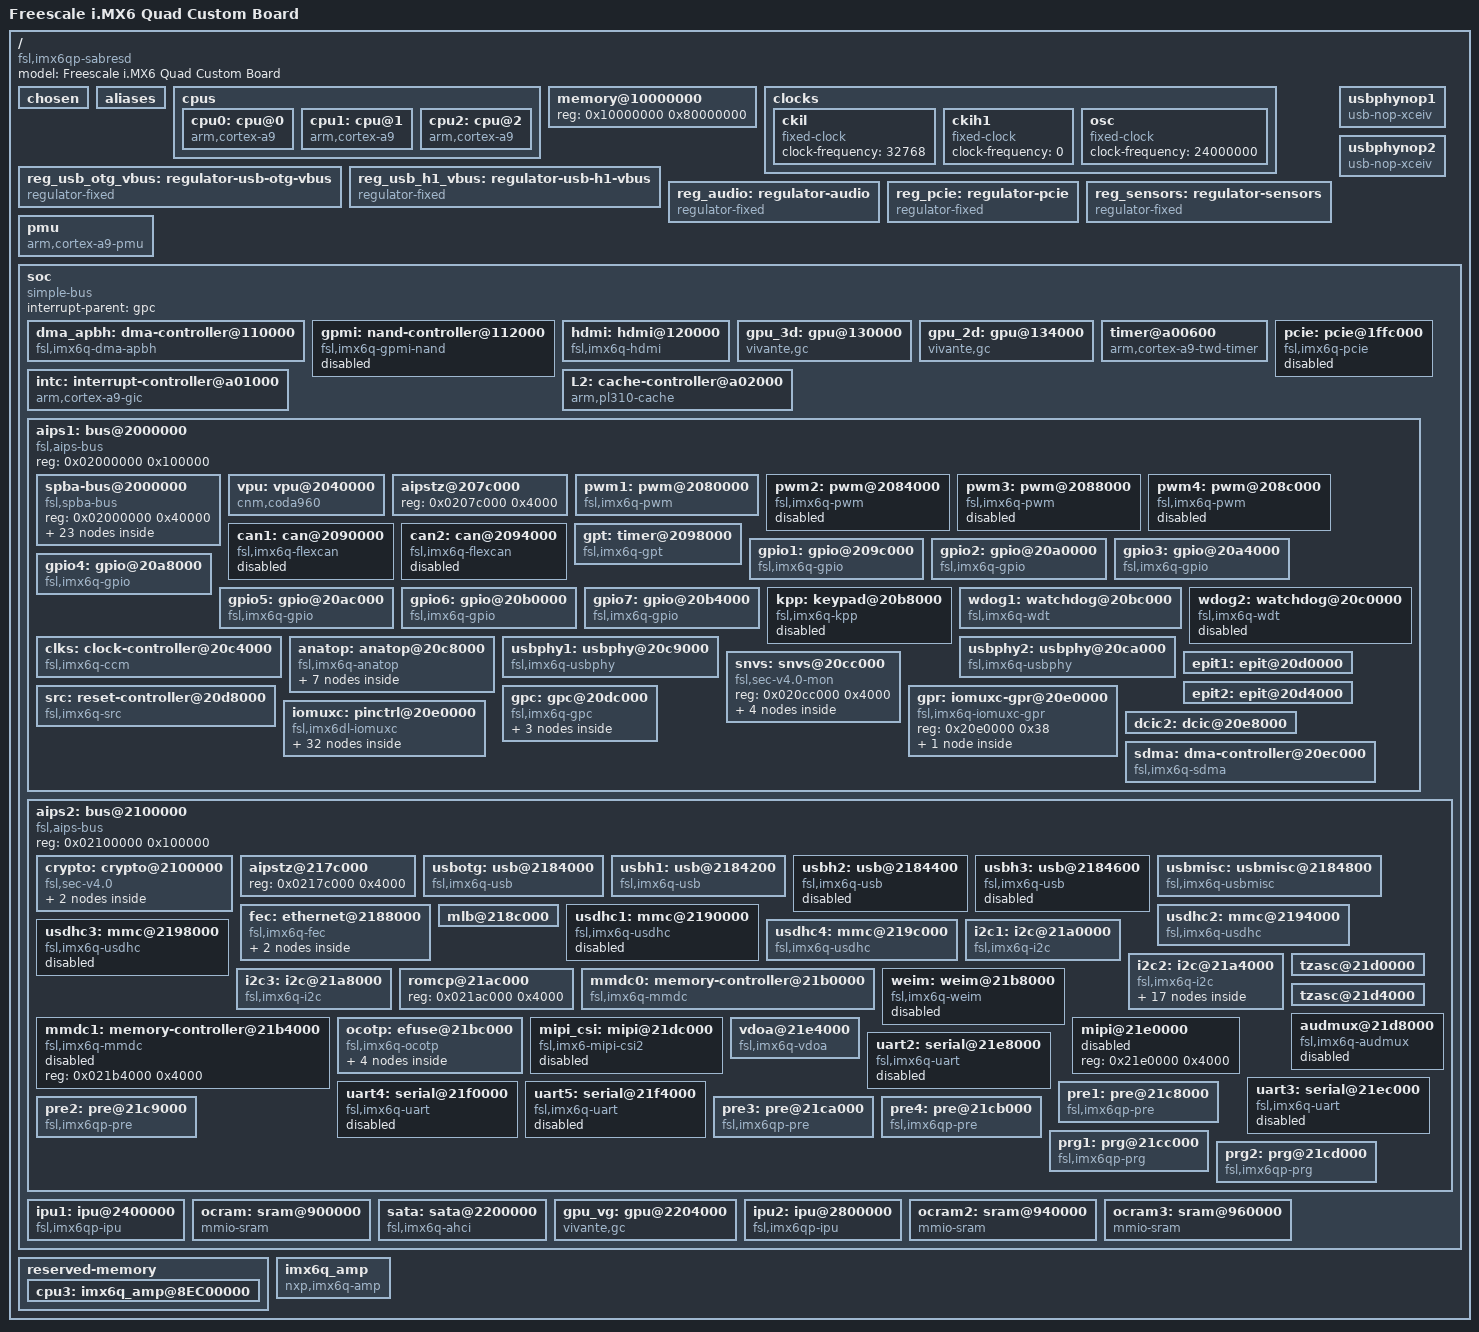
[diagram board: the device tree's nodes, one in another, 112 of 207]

/dts-v1/;
#include <dt-bindings/clock/imx6qdl-clock.h>
#include <dt-bindings/gpio/gpio.h>
#include <dt-bindings/input/input.h>
#include <dt-bindings/interrupt-controller/arm-gic.h>
#include <dt-bindings/interrupt-controller/irq.h>
#include "imx6q-pinfunc.h"
/ {
    #address-cells = <0x1>;
    #size-cells = <0x1>;
    model = "Freescale i.MX6 Quad Custom Board";
    compatible = "fsl,imx6qp-sabresd","fsl,imx6qp";

    chosen {
        stdout-path = "/soc/bus@2000000/spba-bus@2000000/serial@2020000";
    };

    aliases {
        ethernet0 = "/soc/bus@2100000/ethernet@2188000";
        can0 = "/soc/bus@2000000/can@2090000";
        can1 = "/soc/bus@2000000/can@2094000";
        gpio0 = "/soc/bus@2000000/gpio@209c000";
        gpio1 = "/soc/bus@2000000/gpio@20a0000";
        gpio2 = "/soc/bus@2000000/gpio@20a4000";
        gpio3 = "/soc/bus@2000000/gpio@20a8000";
        gpio4 = "/soc/bus@2000000/gpio@20ac000";
        gpio5 = "/soc/bus@2000000/gpio@20b0000";
        gpio6 = "/soc/bus@2000000/gpio@20b4000";
        i2c0 = "/soc/bus@2100000/i2c@21a0000";
        i2c1 = "/soc/bus@2100000/i2c@21a4000";
        i2c2 = "/soc/bus@2100000/i2c@21a8000";
        ipu0 = "/soc/ipu@2400000";
        mmc0 = "/soc/bus@2100000/mmc@2190000";
        mmc1 = "/soc/bus@2100000/mmc@2194000";
        mmc2 = "/soc/bus@2100000/mmc@2198000";
        mmc3 = "/soc/bus@2100000/mmc@219c000";
        serial0 = "/soc/bus@2000000/spba-bus@2000000/serial@2020000";
        serial1 = "/soc/bus@2100000/serial@21e8000";
        serial2 = "/soc/bus@2100000/serial@21ec000";
        serial3 = "/soc/bus@2100000/serial@21f0000";
        serial4 = "/soc/bus@2100000/serial@21f4000";
        spi0 = "/soc/bus@2000000/spba-bus@2000000/spi@2008000";
        spi1 = "/soc/bus@2000000/spba-bus@2000000/spi@200c000";
        spi2 = "/soc/bus@2000000/spba-bus@2000000/spi@2010000";
        spi3 = "/soc/bus@2000000/spba-bus@2000000/spi@2014000";
        usb0 = "/soc/bus@2100000/usb@2184000";
        usb1 = "/soc/bus@2100000/usb@2184200";
        usb2 = "/soc/bus@2100000/usb@2184400";
        usb3 = "/soc/bus@2100000/usb@2184600";
        usbphy0 = "/soc/bus@2000000/usbphy@20c9000";
        usbphy1 = "/soc/bus@2000000/usbphy@20ca000";
        ipu1 = "/soc/ipu@2800000";
        spi4 = "/soc/bus@2000000/spba-bus@2000000/spi@2018000";
    };
    cpus {
        #address-cells = <1>;
        #size-cells = <0>;

        cpu0: cpu@0 {
            compatible = "arm,cortex-a9";
            device_type = "cpu";
            reg = <0>;
            next-level-cache = <&L2>;
            operating-points = <
                /* kHz    uV */
                1200000 1275000
                996000  1250000
                852000  1250000
                792000  1175000
                396000  975000
            >;
            fsl,soc-operating-points = <
                /* ARM kHz  SOC-PU uV */
                1200000 1275000
                996000  1250000
                852000  1250000
                792000  1175000
                396000  1175000
            >;
            clock-latency = <61036>; /* two CLK32 periods */
            #cooling-cells = <2>;
            clocks = <&clks IMX6QDL_CLK_ARM>,
                 <&clks IMX6QDL_CLK_PLL2_PFD2_396M>,
                 <&clks IMX6QDL_CLK_STEP>,
                 <&clks IMX6QDL_CLK_PLL1_SW>,
                 <&clks IMX6QDL_CLK_PLL1_SYS>,
				 <&clks IMX6QDL_CLK_PLL1>,
				 <&clks IMX6QDL_PLL1_BYPASS>,
				 <&clks IMX6QDL_PLL1_BYPASS_SRC>;
            clock-names = "arm", "pll2_pfd2_396m", "step",
                      "pll1_sw", "pll1_sys","pll1","pll1_bypass", "pll1_bypass_src";
            arm-supply = <&reg_arm>;
            pu-supply = <&reg_pu>;
            soc-supply = <&reg_soc>;
            nvmem-cells = <&cpu_speed_grade>;
            nvmem-cell-names = "speed_grade";
        };

        cpu1: cpu@1 {
            compatible = "arm,cortex-a9";
            device_type = "cpu";
            reg = <1>;
            next-level-cache = <&L2>;
            operating-points = <
                /* kHz    uV */
                1200000 1275000
                996000  1250000
                852000  1250000
                792000  1175000
                396000  975000
            >;
            fsl,soc-operating-points = <
                /* ARM kHz  SOC-PU uV */
                1200000 1275000
                996000  1250000
                852000  1250000
                792000  1175000
                396000  1175000
            >;
            clock-latency = <61036>; /* two CLK32 periods */
            #cooling-cells = <2>;
            clocks = <&clks IMX6QDL_CLK_ARM>,
                 <&clks IMX6QDL_CLK_PLL2_PFD2_396M>,
                 <&clks IMX6QDL_CLK_STEP>,
                 <&clks IMX6QDL_CLK_PLL1_SW>,
                 <&clks IMX6QDL_CLK_PLL1_SYS>,
				 <&clks IMX6QDL_CLK_PLL1>,
				 <&clks IMX6QDL_PLL1_BYPASS>,
				 <&clks IMX6QDL_PLL1_BYPASS_SRC>;
            clock-names = "arm", "pll2_pfd2_396m", "step",
                      "pll1_sw", "pll1_sys","pll1","pll1_bypass", "pll1_bypass_src";
            
		    arm-supply = <&reg_arm>;
            pu-supply = <&reg_pu>;
            soc-supply = <&reg_soc>;
        };

        cpu2: cpu@2 {
            compatible = "arm,cortex-a9";
            device_type = "cpu";
            reg = <2>;
            next-level-cache = <&L2>;
            operating-points = <
                /* kHz    uV */
                1200000 1275000
                996000  1250000
                852000  1250000
                792000  1175000
                396000  975000
            >;
            fsl,soc-operating-points = <
                /* ARM kHz  SOC-PU uV */
                1200000 1275000
                996000  1250000
                852000  1250000
                792000  1175000
                396000  1175000
            >;
            clock-latency = <61036>; /* two CLK32 periods */
            #cooling-cells = <2>;
            clocks = <&clks IMX6QDL_CLK_ARM>,
                 <&clks IMX6QDL_CLK_PLL2_PFD2_396M>,
                 <&clks IMX6QDL_CLK_STEP>,
                 <&clks IMX6QDL_CLK_PLL1_SW>,
                 <&clks IMX6QDL_CLK_PLL1_SYS>,
    			 <&clks IMX6QDL_CLK_PLL1>,
				 <&clks IMX6QDL_PLL1_BYPASS>,
				 <&clks IMX6QDL_PLL1_BYPASS_SRC>;
            clock-names = "arm", "pll2_pfd2_396m", "step",
                      "pll1_sw", "pll1_sys","pll1","pll1_bypass", "pll1_bypass_src";
			arm-supply = <&reg_arm>;
            pu-supply = <&reg_pu>;
            soc-supply = <&reg_soc>;
        };

//         cpu3: cpu@3 {
//             compatible = "arm,cortex-a9";
//             device_type = "cpu";
//             reg = <3>;
//             next-level-cache = <&L2>;
//             operating-points = <
//                 /* kHz    uV */
//                 1200000 1275000
//                 996000  1250000
//                 852000  1250000
//                 792000  1175000
//                 396000  975000
//             >;
//             fsl,soc-operating-points = <
//                 /* ARM kHz  SOC-PU uV */
//                 1200000 1275000
//                 996000  1250000
//                 852000  1250000
//                 792000  1175000
//                 396000  1175000
//             >;
//             clock-latency = <61036>; /* two CLK32 periods */
//             #cooling-cells = <2>;
//             clocks = <&clks IMX6QDL_CLK_ARM>,
//                  <&clks IMX6QDL_CLK_PLL2_PFD2_396M>,
//                  <&clks IMX6QDL_CLK_STEP>,
//                  <&clks IMX6QDL_CLK_PLL1_SW>,
//                  <&clks IMX6QDL_CLK_PLL1_SYS>,
//         		 <&clks IMX6QDL_CLK_PLL1>,
// 				 <&clks IMX6QDL_PLL1_BYPASS>,
// 				 <&clks IMX6QDL_PLL1_BYPASS_SRC>;
//             clock-names = "arm", "pll2_pfd2_396m", "step",
//                       "pll1_sw", "pll1_sys","pll1","pll1_bypass", "pll1_bypass_src";
// 			arm-supply = <&reg_arm>;
//             pu-supply = <&reg_pu>;
//             soc-supply = <&reg_soc>;
//         };

    };
    memory@10000000 {
        device_type = "memory";
        reg = <0x10000000 0x80000000>;
    };
    
    clocks {

        ckil {
            compatible = "fixed-clock";
            #clock-cells = <0>;
            clock-frequency = <32768>;
        };

        ckih1 {
            compatible = "fixed-clock";
            #clock-cells = <0>;
            clock-frequency = <0>;
        };

        osc {
            compatible = "fixed-clock";
            #clock-cells = <0>;
            clock-frequency = <24000000>;
        };
    };
    
    reg_usb_otg_vbus: regulator-usb-otg-vbus {
        compatible = "regulator-fixed";
        regulator-name = "usb_otg_vbus";
        regulator-min-microvolt = <5000000>;
        regulator-max-microvolt = <5000000>;
        gpio = <&gpio3 22 GPIO_ACTIVE_HIGH>;
        enable-active-high;
        vin-supply = <&swbst_reg>;
    };

    reg_usb_h1_vbus: regulator-usb-h1-vbus {
        compatible = "regulator-fixed";
        regulator-name = "usb_h1_vbus";
        regulator-min-microvolt = <5000000>;
        regulator-max-microvolt = <5000000>;
        gpio = <&gpio1 29 GPIO_ACTIVE_HIGH>;
        enable-active-high;
        vin-supply = <&swbst_reg>;
    };

    reg_audio: regulator-audio {
        compatible = "regulator-fixed";
        regulator-name = "wm8962-supply";
        gpio = <&gpio4 10 GPIO_ACTIVE_HIGH>;
        enable-active-high;
    };

    reg_pcie: regulator-pcie {
        compatible = "regulator-fixed";
        pinctrl-names = "default";
        //pinctrl-0 = <&pinctrl_pcie_reg>;
        regulator-name = "MPCIE_3V3";
        regulator-min-microvolt = <3300000>;
        regulator-max-microvolt = <3300000>;
        //gpio = <&gpio3 19 GPIO_ACTIVE_HIGH>;
        enable-active-high;
    };

    reg_sensors: regulator-sensors {
        compatible = "regulator-fixed";
        pinctrl-names = "default";
        pinctrl-0 = <&pinctrl_sensors_reg>;
        regulator-name = "sensors-supply";
        regulator-min-microvolt = <3300000>;
        regulator-max-microvolt = <3300000>;
        gpio = <&gpio2 31 GPIO_ACTIVE_HIGH>;
        enable-active-high;
    };

    pmu: pmu {
        compatible = "arm,cortex-a9-pmu";
        interrupt-parent = <&gpc>;
        interrupts = <0 94 IRQ_TYPE_LEVEL_HIGH>;
    };

    usbphynop1: usbphynop1 {
                compatible = "usb-nop-xceiv";
                #phy-cells = <0>;
            };

    usbphynop2: usbphynop2 {
                compatible = "usb-nop-xceiv";
                #phy-cells = <0>;
            };
             
    soc: soc {
        #address-cells = <1>;
        #size-cells = <1>;
        compatible = "simple-bus";
        interrupt-parent = <&gpc>;
        ranges;

        dma_apbh: dma-controller@110000 {
            compatible = "fsl,imx6q-dma-apbh", "fsl,imx28-dma-apbh";
            reg = <0x00110000 0x2000>;
            interrupts = <0 13 IRQ_TYPE_LEVEL_HIGH>,
                     <0 13 IRQ_TYPE_LEVEL_HIGH>,
                     <0 13 IRQ_TYPE_LEVEL_HIGH>,
                     <0 13 IRQ_TYPE_LEVEL_HIGH>;
			interrupt-names = "gpmi0", "gpmi1", "gpmi2", "gpmi3";
            #dma-cells = <1>;
            dma-channels = <4>;
            clocks = <&clks IMX6QDL_CLK_APBH_DMA>;
        };

        gpmi: nand-controller@112000 {
            compatible = "fsl,imx6q-gpmi-nand";
            reg = <0x00112000 0x2000>, <0x00114000 0x2000>;
            reg-names = "gpmi-nand", "bch";
            interrupts = <0 15 IRQ_TYPE_LEVEL_HIGH>;
            interrupt-names = "bch";
            clocks = <&clks IMX6QDL_CLK_GPMI_IO>,
                 <&clks IMX6QDL_CLK_GPMI_APB>,
                 <&clks IMX6QDL_CLK_GPMI_BCH>,
                 <&clks IMX6QDL_CLK_GPMI_BCH_APB>,
                 <&clks IMX6QDL_CLK_PER1_BCH>;
            clock-names = "gpmi_io", "gpmi_apb", "gpmi_bch",
                      "gpmi_bch_apb", "per1_bch";
            dmas = <&dma_apbh 0>;
            dma-names = "rx-tx";
            status = "disabled";
        };

        hdmi: hdmi@120000 {
            reg = <0x00120000 0x9000>;
            interrupts = <0 115 0x04>;
            gpr = <&gpr>;
            clocks = <&clks IMX6QDL_CLK_HDMI_IAHB>,
                 <&clks IMX6QDL_CLK_HDMI_ISFR>;
            clock-names = "iahb", "isfr";
            status = "okay";
            compatible = "fsl,imx6q-hdmi";
            pinctrl-names = "default";
            pinctrl-0 = <&pinctrl_hdmi_cec>;
            ddc-i2c-bus = <&i2c2>;
        };

        gpu_3d: gpu@130000 {
            compatible = "vivante,gc";
            reg = <0x00130000 0x4000>;
            interrupts = <0 9 IRQ_TYPE_LEVEL_HIGH>;
            clocks = <&clks IMX6QDL_CLK_GPU3D_AXI>,
                 <&clks IMX6QDL_CLK_GPU3D_CORE>,
                 <&clks IMX6QDL_CLK_GPU3D_SHADER>;
            clock-names = "bus", "core", "shader";
            power-domains = <&pd_pu>;
            #cooling-cells = <2>;
        };

        gpu_2d: gpu@134000 {
            compatible = "vivante,gc";
            reg = <0x00134000 0x4000>;
            interrupts = <0 10 IRQ_TYPE_LEVEL_HIGH>;
            clocks = <&clks IMX6QDL_CLK_GPU2D_AXI>,
                 <&clks IMX6QDL_CLK_GPU2D_CORE>;
            clock-names = "bus", "core";
            power-domains = <&pd_pu>;
            #cooling-cells = <2>;
        };

        timer@a00600 {
            compatible = "arm,cortex-a9-twd-timer";
            reg = <0x00a00600 0x20>;
            interrupts = <1 13 0xf01>;
            interrupt-parent = <&intc>;
            clocks = <&clks IMX6QDL_CLK_TWD>;
        };

        intc: interrupt-controller@a01000 {
            compatible = "arm,cortex-a9-gic";
            #interrupt-cells = <3>;
            interrupt-controller;
            reg = <0x00a01000 0x1000>,
                  <0x00a00100 0x100>;
            interrupt-parent = <&intc>;
        };

        L2: cache-controller@a02000 {
            compatible = "arm,pl310-cache";
            reg = <0x00a02000 0x1000>;
            interrupts = <0 92 IRQ_TYPE_LEVEL_HIGH>;
            cache-unified;
            cache-level = <2>;
            arm,tag-latency = <4 2 3>;
            arm,data-latency = <4 2 3>;
            arm,shared-override;
        };

        pcie: pcie@1ffc000 {
            compatible = "fsl,imx6q-pcie";
            reg = <0x01ffc000 0x04000>,
                  <0x01f00000 0x80000>;
            reg-names = "dbi", "config";
            #address-cells = <3>;
            #size-cells = <2>;
            device_type = "pci";
            bus-range = <0x00 0xff>;
            ranges = <0x81000000 0 0 0x01f80000 0 0x00010000>, /* downstream I/O */
                 <0x82000000 0 0x01000000 0x01000000 0 0x00f00000>; /* non-prefetchable memory */
            num-lanes = <1>;
            interrupts = <GIC_SPI 120 IRQ_TYPE_LEVEL_HIGH>;
            interrupt-names = "msi";
            #interrupt-cells = <1>;
            interrupt-map-mask = <0 0 0 0x7>;
            interrupt-map = <0 0 0 1 &gpc GIC_SPI 123 IRQ_TYPE_LEVEL_HIGH>,
                    <0 0 0 2 &gpc GIC_SPI 122 IRQ_TYPE_LEVEL_HIGH>,
                    <0 0 0 3 &gpc GIC_SPI 121 IRQ_TYPE_LEVEL_HIGH>,
                    <0 0 0 4 &gpc GIC_SPI 120 IRQ_TYPE_LEVEL_HIGH>;
            clocks = <&clks IMX6QDL_CLK_PCIE_AXI>,
                 <&clks IMX6QDL_CLK_LVDS1_GATE>,
                 <&clks IMX6QDL_CLK_PCIE_REF_125M>;         
                clock-names = "pcie", "pcie_bus", "pcie_phy";
            status = "disabled";
                    pinctrl-names = "default";
                    pinctrl-0 = <&pinctrl_pcie>;
                    reset-gpio = <&gpio7 12 GPIO_ACTIVE_LOW>;
                    vpcie-supply = <&reg_pcie>;
        };

        aips1: bus@2000000 { /* AIPS1 */
            compatible = "fsl,aips-bus", "simple-bus";
            #address-cells = <1>;
            #size-cells = <1>;
            reg = <0x02000000 0x100000>;
            ranges;

            spba-bus@2000000 {
                compatible = "fsl,spba-bus", "simple-bus";
                #address-cells = <1>;
                #size-cells = <1>;
                reg = <0x02000000 0x40000>;
                ranges;

                spdif: spdif@2004000 {
                    compatible = "fsl,imx35-spdif";
                    reg = <0x02004000 0x4000>;
                    interrupts = <0 52 IRQ_TYPE_LEVEL_HIGH>;
                    dmas = <&sdma 14 18 0>,
                           <&sdma 15 18 0>;
                    dma-names = "rx", "tx";
                    clocks = <&clks IMX6QDL_CLK_SPDIF_GCLK>, <&clks IMX6QDL_CLK_OSC>,
                         <&clks IMX6QDL_CLK_SPDIF>, <&clks IMX6QDL_CLK_ASRC>,
                         <&clks IMX6QDL_CLK_DUMMY>, <&clks IMX6QDL_CLK_ESAI_EXTAL>,
                         <&clks IMX6QDL_CLK_IPG>, <&clks IMX6QDL_CLK_DUMMY>,
                         <&clks IMX6QDL_CLK_DUMMY>, <&clks IMX6QDL_CLK_SPBA>;
                    clock-names = "core",  "rxtx0",
                              "rxtx1", "rxtx2",
                              "rxtx3", "rxtx4",
                              "rxtx5", "rxtx6",
                              "rxtx7", "spba";
                    status = "disabled";
                };

                ecspi1: spi@2008000 {
                    #address-cells = <1>;
                    #size-cells = <0>;
                    compatible = "fsl,imx6q-ecspi", "fsl,imx51-ecspi";
                    reg = <0x02008000 0x4000>;
                    interrupts = <0 31 IRQ_TYPE_LEVEL_HIGH>;
                    clocks = <&clks IMX6QDL_CLK_ECSPI1>,
                         <&clks IMX6QDL_CLK_ECSPI1>;
                    clock-names = "ipg", "per";
                    dmas = <&sdma 3 7 1>, <&sdma 4 7 2>;
                    dma-names = "rx", "tx";
                    cs-gpios = <&gpio1 28 GPIO_ACTIVE_LOW>;
                    pinctrl-names = "default";
                    pinctrl-0 = <&pinctrl_ecspi1>;
                    status = "okay";
                    flash: flash@0 {
                        compatible = "winbond,w25q128", "jedec,spi-nor";
                        spi-max-frequency = <50000000>;
                        reg = <0>;
                        /* Flash分区定义 */
                        partitions {
                            compatible = "fixed-partitions";
                            #address-cells = <1>;
                            #size-cells = <1>;

                            /* bootloader分区 - 起始地址0, 大小512KB */
                            partition@0 {
                                label = "uboot";
                                reg = <0x000000 0x80000>;   /* 512KB */
                                read-only;
                            };

                            /* uboot环境变量分区 - 512KB-640KB */
                            partition@80000 {
                                label = "uboot-env";
                                reg = <0x080000 0x20000>;   /* 128KB */
                            };

                            /* 设备树分区 - 640KB-768KB */
                            partition@a0000 {
                                label = "device-tree";
                                reg = <0x0a0000 0x20000>;   /* 128KB */
                            };

                            /* 内核分区 - 768KB-4MB */
                            partition@c0000 {
                                label = "kernel";
                                reg = <0x0c0000 0x340000>;  /* 3.25MB */
                            };

                            /* 根文件系统分区 - 4MB-12MB */
                            partition@400000 {
                                label = "rootfs";
                                reg = <0x400000 0x800000>;  /* 8MB */
                            };

                            /* 用户数据分区 - 12MB-15MB */
                            partition@c00000 {
                                label = "userdata";
                                reg = <0xc00000 0x300000>;  /* 3MB */
                            };

                            /* 环境变量备份分区 - 最后1MB (15MB-16MB) */
                            partition@f00000 {
                                label = "env";
                                reg = <0xf00000 0x100000>;  /* 1MB */
                            };
                        };
                    };
                };

                ecspi2: spi@200c000 {
                    #address-cells = <1>;
                    #size-cells = <0>;
                    compatible = "fsl,imx6q-ecspi", "fsl,imx51-ecspi";
                    reg = <0x0200c000 0x4000>;
                    interrupts = <0 32 IRQ_TYPE_LEVEL_HIGH>;
                    clocks = <&clks IMX6QDL_CLK_ECSPI2>,
                         <&clks IMX6QDL_CLK_ECSPI2>;
                    clock-names = "ipg", "per";
                    dmas = <&sdma 5 7 1>, <&sdma 6 7 2>;
                    dma-names = "rx", "tx";
                    status = "okay";
					pinctrl-names = "default";
					pinctrl-0 = <&pinctrl_ecspi2>;        // 绑定 SPI2 引脚控制组
					//cs-gpios = <&gpio5 29 GPIO_ACTIVE_LOW>;
					ads1282@0 {
						compatible = "ti,ads1282";
				        reg = <0>;
						spi-max-frequency = <2000000>;
						//spi-cpha;
						pinctrl-names = "default";
						pinctrl-0 = <&pinctrl_ads1282_reset &pinctrl_ads1282_sync &pinctrl_ads1282_pwdn &pinctrl_ads1282_irq>;
						interrupt-parent = <&gpio5>; //
						interrupts = <2 IRQ_TYPE_EDGE_FALLING>; // GPIO5_02，下降沿触发 DRDY
						sync-gpios = <&gpio3 21 GPIO_ACTIVE_HIGH>;
						reset-gpios = <&gpio3 20 GPIO_ACTIVE_LOW>;   // 复位引脚，低电平有效
						pwdn-gpios = <&gpio3 19 GPIO_ACTIVE_LOW>; // 电源power down，低电平有效
						drdy-gpios = <&gpio5 2 GPIO_ACTIVE_LOW>; // irq gpio
					};
                };

                ecspi3: spi@2010000 {
                    #address-cells = <1>;
                    #size-cells = <0>;
                    compatible = "fsl,imx6q-ecspi", "fsl,imx51-ecspi";
                    reg = <0x02010000 0x4000>;
                    interrupts = <0 33 IRQ_TYPE_LEVEL_HIGH>;
                    clocks = <&clks IMX6QDL_CLK_ECSPI3>,
                         <&clks IMX6QDL_CLK_ECSPI3>;
                    clock-names = "ipg", "per";
                    dmas = <&sdma 7 7 1>, <&sdma 8 7 2>;
                    dma-names = "rx", "tx";
                    status = "disabled";
                };

                ecspi4: spi@2014000 {
                    #address-cells = <1>;
                    #size-cells = <0>;
                    compatible = "fsl,imx6q-ecspi", "fsl,imx51-ecspi";
                    reg = <0x02014000 0x4000>;
                    interrupts = <0 34 IRQ_TYPE_LEVEL_HIGH>;
                    clocks = <&clks IMX6QDL_CLK_ECSPI4>,
                         <&clks IMX6QDL_CLK_ECSPI4>;
                    clock-names = "ipg", "per";
                    dmas = <&sdma 9 7 1>, <&sdma 10 7 2>;
                    dma-names = "rx", "tx";
                    status = "disabled";
                };
                ecspi5: spi@2018000 {
                    #address-cells = <1>;
                    #size-cells = <0>;
                    compatible = "fsl,imx6q-ecspi", "fsl,imx51-ecspi";
                    reg = <0x02018000 0x4000>;
                    interrupts = <0 35 IRQ_TYPE_LEVEL_HIGH>;
                    clocks = <&clks IMX6Q_CLK_ECSPI5>,
                         <&clks IMX6Q_CLK_ECSPI5>;
                    clock-names = "ipg", "per";
                    dmas = <&sdma 11 7 1>, <&sdma 12 7 2>;
                    dma-names = "rx", "tx";
                    status = "disabled";
                };
                uart1: serial@2020000 {
                    compatible = "fsl,imx6q-uart", "fsl,imx21-uart";
                    reg = <0x02020000 0x4000>;
                    interrupts = <0 26 IRQ_TYPE_LEVEL_HIGH>;
                    clocks = <&clks IMX6QDL_CLK_UART_IPG>,
                         <&clks IMX6QDL_CLK_UART_SERIAL>;
                    clock-names = "ipg", "per";
                    dmas = <&sdma 25 4 0>, <&sdma 26 4 0>;
                    dma-names = "rx", "tx";
                    status = "okay";
                    pinctrl-names = "default";
                    pinctrl-0 = <&pinctrl_uart1>;
                };

                esai: esai@2024000 {
                    #sound-dai-cells = <0>;
                    compatible = "fsl,imx35-esai";
                    reg = <0x02024000 0x4000>;
                    interrupts = <0 51 IRQ_TYPE_LEVEL_HIGH>;
                    clocks = <&clks IMX6QDL_CLK_ESAI_IPG>,
                         <&clks IMX6QDL_CLK_ESAI_MEM>,
                         <&clks IMX6QDL_CLK_ESAI_EXTAL>,
                         <&clks IMX6QDL_CLK_ESAI_IPG>,
                         <&clks IMX6QDL_CLK_SPBA>;
                    clock-names = "core", "mem", "extal", "fsys", "spba";
                    dmas = <&sdma 23 21 0>, <&sdma 24 21 0>;
                    dma-names = "rx", "tx";
                    status = "disabled";
                };

                ssi1: ssi@2028000 {
                    #sound-dai-cells = <0>;
                    compatible = "fsl,imx6q-ssi",
                            "fsl,imx51-ssi";
                    reg = <0x02028000 0x4000>;
                    interrupts = <0 46 IRQ_TYPE_LEVEL_HIGH>;
                    clocks = <&clks IMX6QDL_CLK_SSI1_IPG>,
                         <&clks IMX6QDL_CLK_SSI1>;
                    clock-names = "ipg", "baud";
                    dmas = <&sdma 37 1 0>,
                           <&sdma 38 1 0>;
                    dma-names = "rx", "tx";
                    fsl,fifo-depth = <15>;
                    status = "disabled";
                };

                ssi2: ssi@202c000 {
                    #sound-dai-cells = <0>;
                    compatible = "fsl,imx6q-ssi",
                            "fsl,imx51-ssi";
                    reg = <0x0202c000 0x4000>;
                    interrupts = <0 47 IRQ_TYPE_LEVEL_HIGH>;
                    clocks = <&clks IMX6QDL_CLK_SSI2_IPG>,
                         <&clks IMX6QDL_CLK_SSI2>;
                    clock-names = "ipg", "baud";
                    dmas = <&sdma 41 1 0>,
                           <&sdma 42 1 0>;
                    dma-names = "rx", "tx";
                    fsl,fifo-depth = <15>;
                    status = "okay";
                };

                ssi3: ssi@2030000 {
                    #sound-dai-cells = <0>;
                    compatible = "fsl,imx6q-ssi",
                            "fsl,imx51-ssi";
                    reg = <0x02030000 0x4000>;
                    interrupts = <0 48 IRQ_TYPE_LEVEL_HIGH>;
                    clocks = <&clks IMX6QDL_CLK_SSI3_IPG>,
                         <&clks IMX6QDL_CLK_SSI3>;
                    clock-names = "ipg", "baud";
                    dmas = <&sdma 45 1 0>,
                           <&sdma 46 1 0>;
                    dma-names = "rx", "tx";
                    fsl,fifo-depth = <15>;
                    status = "disabled";
                };

                asrc: asrc@2034000 {
                    compatible = "fsl,imx53-asrc";
                    reg = <0x02034000 0x4000>;
                    interrupts = <0 50 IRQ_TYPE_LEVEL_HIGH>;
                    clocks = <&clks IMX6QDL_CLK_ASRC_IPG>,
                        <&clks IMX6QDL_CLK_ASRC_MEM>, <&clks 0>,
                        <&clks 0>, <&clks 0>, <&clks 0>, <&clks 0>,
                        <&clks 0>, <&clks 0>, <&clks 0>, <&clks 0>,
                        <&clks 0>, <&clks 0>, <&clks 0>, <&clks 0>,
                        <&clks IMX6QDL_CLK_ASRC>, <&clks 0>, <&clks 0>,
                        <&clks IMX6QDL_CLK_SPBA>;
                    clock-names = "mem", "ipg", "asrck_0",
                        "asrck_1", "asrck_2", "asrck_3", "asrck_4",
                        "asrck_5", "asrck_6", "asrck_7", "asrck_8",
                        "asrck_9", "asrck_a", "asrck_b", "asrck_c",
                        "asrck_d", "asrck_e", "asrck_f", "spba";
                    dmas = <&sdma 17 23 1>, <&sdma 18 23 1>, <&sdma 19 23 1>,
                        <&sdma 20 23 1>, <&sdma 21 23 1>, <&sdma 22 23 1>;
                    dma-names = "rxa", "rxb", "rxc",
                            "txa", "txb", "txc";
                    fsl,asrc-rate  = <48000>;
                    fsl,asrc-width = <16>;
                    status = "okay";
                };

                spba-bus@203c000 {
                    reg = <0x0203c000 0x4000>;
                };
            };

            vpu: vpu@2040000 {
                compatible = "cnm,coda960";
                reg = <0x02040000 0x3c000>;
                interrupts = <0 12 IRQ_TYPE_LEVEL_HIGH>,
                         <0 3 IRQ_TYPE_LEVEL_HIGH>;
                interrupt-names = "bit", "jpeg";
                clocks = <&clks IMX6QDL_CLK_VPU_AXI>,
                     <&clks IMX6QDL_CLK_MMDC_CH0_AXI>;
                clock-names = "per", "ahb";
                power-domains = <&pd_pu>;
                resets = <&src 1>;
                iram = <&ocram>;
            };

            aipstz@207c000 { /* AIPSTZ1 */
                reg = <0x0207c000 0x4000>;
            };

            pwm1: pwm@2080000 {
                #pwm-cells = <3>;
                compatible = "fsl,imx6q-pwm", "fsl,imx27-pwm";
                reg = <0x02080000 0x4000>;
                interrupts = <0 83 IRQ_TYPE_LEVEL_HIGH>;
                clocks = <&clks IMX6QDL_CLK_IPG>,
                     <&clks IMX6QDL_CLK_PWM1>;
                clock-names = "ipg", "per";
                status = "okay";
                pinctrl-names = "default";
                pinctrl-0 = <&pinctrl_pwm1>;
            };

            pwm2: pwm@2084000 {
                #pwm-cells = <3>;
                compatible = "fsl,imx6q-pwm", "fsl,imx27-pwm";
                reg = <0x02084000 0x4000>;
                interrupts = <0 84 IRQ_TYPE_LEVEL_HIGH>;
                clocks = <&clks IMX6QDL_CLK_IPG>,
                     <&clks IMX6QDL_CLK_PWM2>;
                clock-names = "ipg", "per";
                status = "disabled";
            };

            pwm3: pwm@2088000 {
                #pwm-cells = <3>;
                compatible = "fsl,imx6q-pwm", "fsl,imx27-pwm";
                reg = <0x02088000 0x4000>;
                interrupts = <0 85 IRQ_TYPE_LEVEL_HIGH>;
                clocks = <&clks IMX6QDL_CLK_IPG>,
                     <&clks IMX6QDL_CLK_PWM3>;
                clock-names = "ipg", "per";
                status = "disabled";
            };

            pwm4: pwm@208c000 {
                #pwm-cells = <3>;
                compatible = "fsl,imx6q-pwm", "fsl,imx27-pwm";
                reg = <0x0208c000 0x4000>;
                interrupts = <0 86 IRQ_TYPE_LEVEL_HIGH>;
                clocks = <&clks IMX6QDL_CLK_IPG>,
                     <&clks IMX6QDL_CLK_PWM4>;
                clock-names = "ipg", "per";
                status = "disabled";
            };

            can1: can@2090000 {
                compatible = "fsl,imx6q-flexcan";
                reg = <0x02090000 0x4000>;
                interrupts = <0 110 IRQ_TYPE_LEVEL_HIGH>;
                clocks = <&clks IMX6QDL_CLK_CAN1_IPG>,
                     <&clks IMX6QDL_CLK_CAN1_SERIAL>;
                clock-names = "ipg", "per";
                fsl,stop-mode = <&gpr 0x34 28>;
                status = "disabled";
            };

            can2: can@2094000 {
                compatible = "fsl,imx6q-flexcan";
                reg = <0x02094000 0x4000>;
                interrupts = <0 111 IRQ_TYPE_LEVEL_HIGH>;
                clocks = <&clks IMX6QDL_CLK_CAN2_IPG>,
                     <&clks IMX6QDL_CLK_CAN2_SERIAL>;
                clock-names = "ipg", "per";
                fsl,stop-mode = <&gpr 0x34 29>;
                status = "disabled";
            };

            gpt: timer@2098000 {
                compatible = "fsl,imx6q-gpt", "fsl,imx31-gpt";
                reg = <0x02098000 0x4000>;
                interrupts = <0 55 IRQ_TYPE_LEVEL_HIGH>;
                clocks = <&clks IMX6QDL_CLK_GPT_IPG>,
                     <&clks IMX6QDL_CLK_GPT_IPG_PER>,
                     <&clks IMX6QDL_CLK_GPT_3M>;
                clock-names = "ipg", "per", "osc_per";
            };

            gpio1: gpio@209c000 {
                compatible = "fsl,imx6q-gpio", "fsl,imx35-gpio";
                reg = <0x0209c000 0x4000>;
                interrupts = <0 66 IRQ_TYPE_LEVEL_HIGH>,
                         <0 67 IRQ_TYPE_LEVEL_HIGH>;
                gpio-controller;
                #gpio-cells = <2>;
                interrupt-controller;
                #interrupt-cells = <2>;
                gpio-ranges = <&iomuxc  0 136  2>, <&iomuxc  2 141 1>, <&iomuxc  3 139 1>,
                      <&iomuxc  4 142  2>, <&iomuxc  6 140 1>, <&iomuxc  7 144 2>,
                      <&iomuxc  9 138  1>, <&iomuxc 10 213 3>, <&iomuxc 13  20 1>,
                      <&iomuxc 14  19  1>, <&iomuxc 15  21 1>, <&iomuxc 16 208 1>,
                      <&iomuxc 17 207  1>, <&iomuxc 18 210 3>, <&iomuxc 21 209 1>,
                      <&iomuxc 22 116 10>;
            };

            gpio2: gpio@20a0000 {
                compatible = "fsl,imx6q-gpio", "fsl,imx35-gpio";
                reg = <0x020a0000 0x4000>;
                interrupts = <0 68 IRQ_TYPE_LEVEL_HIGH>,
                         <0 69 IRQ_TYPE_LEVEL_HIGH>;
                gpio-controller;
                #gpio-cells = <2>;
                interrupt-controller;
                #interrupt-cells = <2>;
                pio-ranges = <&iomuxc  0 191 16>, <&iomuxc 16 55 14>, <&iomuxc 30 35 1>,
                            <&iomuxc 31  44  1>;
            };

            gpio3: gpio@20a4000 {
                compatible = "fsl,imx6q-gpio", "fsl,imx35-gpio";
                reg = <0x020a4000 0x4000>;
                interrupts = <0 70 IRQ_TYPE_LEVEL_HIGH>,
                         <0 71 IRQ_TYPE_LEVEL_HIGH>;
                gpio-controller;
                #gpio-cells = <2>;
                interrupt-controller;
                #interrupt-cells = <2>;
                gpio-ranges = <&iomuxc 0 69 16>, <&iomuxc 16 36 8>, <&iomuxc 24 45 8>;
            };

            gpio4: gpio@20a8000 {
                compatible = "fsl,imx6q-gpio", "fsl,imx35-gpio";
                reg = <0x020a8000 0x4000>;
                interrupts = <0 72 IRQ_TYPE_LEVEL_HIGH>,
                         <0 73 IRQ_TYPE_LEVEL_HIGH>;
                gpio-controller;
                #gpio-cells = <2>;
                interrupt-controller;
                #interrupt-cells = <2>;
                gpio-ranges = <&iomuxc 5 149 1>, <&iomuxc 6 126 10>, <&iomuxc 16 87 16>;
            };

            gpio5: gpio@20ac000 {
                compatible = "fsl,imx6q-gpio", "fsl,imx35-gpio";
                reg = <0x020ac000 0x4000>;
                interrupts = <0 74 IRQ_TYPE_LEVEL_HIGH>,
                         <0 75 IRQ_TYPE_LEVEL_HIGH>;
                gpio-controller;
                #gpio-cells = <2>;
                interrupt-controller;
                #interrupt-cells = <0x02>;
                gpio-ranges = <&iomuxc 0  85  1>, <&iomuxc  2  34  1>, <&iomuxc 4 53 1>,
                                  <&iomuxc 5 103 13>, <&iomuxc 18 150 14>;
            };

            gpio6: gpio@20b0000 {
                compatible = "fsl,imx6q-gpio", "fsl,imx35-gpio";
                reg = <0x020b0000 0x4000>;
                interrupts = <0 76 IRQ_TYPE_LEVEL_HIGH>,
                         <0 77 IRQ_TYPE_LEVEL_HIGH>;
                gpio-controller;
                #gpio-cells = <2>;
                interrupt-controller;
                #interrupt-cells = <0x02>;
                gpio-ranges = <&iomuxc  0 164 6>, <&iomuxc  6  54 1>, <&iomuxc  7 181  5>,
                 <&iomuxc 14 186 3>, <&iomuxc 17 170 2>, <&iomuxc 19  22 12>,
                 <&iomuxc 31  86 1>;
            };

            gpio7: gpio@20b4000 {
                compatible = "fsl,imx6q-gpio", "fsl,imx35-gpio";
                reg = <0x020b4000 0x4000>;
                interrupts = <0 78 IRQ_TYPE_LEVEL_HIGH>,
                         <0 79 IRQ_TYPE_LEVEL_HIGH>;
                gpio-controller;
                #gpio-cells = <2>;
                interrupt-controller;
                #interrupt-cells = <2>;
                gpio-ranges = <&iomuxc 0 172 9>, <&iomuxc 9 189 2>, <&iomuxc 11 146 3>;
            };

            kpp: keypad@20b8000 {
                compatible = "fsl,imx6q-kpp", "fsl,imx21-kpp";
                reg = <0x020b8000 0x4000>;
                interrupts = <0 82 IRQ_TYPE_LEVEL_HIGH>;
                clocks = <&clks IMX6QDL_CLK_IPG>;
                status = "disabled";
            };

            wdog1: watchdog@20bc000 {
                compatible = "fsl,imx6q-wdt", "fsl,imx21-wdt";
                reg = <0x020bc000 0x4000>;
                interrupts = <0 80 IRQ_TYPE_LEVEL_HIGH>;
                clocks = <&clks IMX6QDL_CLK_IPG>;
                status = "okay";
            };

            wdog2: watchdog@20c0000 {
                compatible = "fsl,imx6q-wdt", "fsl,imx21-wdt";
                reg = <0x020c0000 0x4000>;
                interrupts = <0 81 IRQ_TYPE_LEVEL_HIGH>;
                clocks = <&clks IMX6QDL_CLK_IPG>;
                status = "disabled";
                pinctrl-names = "default";
                pinctrl-0 = <&pinctrl_wdog>;
                fsl,ext-reset-output;
            };

            clks: clock-controller@20c4000 {
                compatible = "fsl,imx6q-ccm";
                reg = <0x020c4000 0x4000>;
                interrupts = <0 87 IRQ_TYPE_LEVEL_HIGH>,
                             <0 88 IRQ_TYPE_LEVEL_HIGH>;
                #clock-cells = <1>;
                assigned-clocks = <&clks IMX6QDL_CLK_LDB_DI0_SEL>,
                       <&clks IMX6QDL_CLK_LDB_DI1_SEL>;
                assigned-clock-parents = <&clks IMX6QDL_CLK_PLL3_USB_OTG>,
                       <&clks IMX6QDL_CLK_PLL3_USB_OTG>;

            };

            anatop: anatop@20c8000 {
                compatible = "fsl,imx6q-anatop", "syscon", "simple-mfd";
                reg = <0x020c8000 0x1000>;
                interrupts = <0 49 IRQ_TYPE_LEVEL_HIGH>,
                         <0 54 IRQ_TYPE_LEVEL_HIGH>,
                         <0 127 IRQ_TYPE_LEVEL_HIGH>;

                reg_vdd1p1: regulator-1p1 {
                    compatible = "fsl,anatop-regulator";
                    regulator-name = "vdd1p1";
                    regulator-min-microvolt = <1000000>;
                    regulator-max-microvolt = <1200000>;
                    regulator-always-on;
                    anatop-reg-offset = <0x110>;
                    anatop-vol-bit-shift = <8>;
                    anatop-vol-bit-width = <5>;
                    anatop-min-bit-val = <4>;
                    anatop-min-voltage = <800000>;
                    anatop-max-voltage = <1375000>;
                    anatop-enable-bit = <0>;
                    vin-supply = <&vgen5_reg>;
                };

                reg_vdd3p0: regulator-3p0 {
                    compatible = "fsl,anatop-regulator";
                    regulator-name = "vdd3p0";
                    regulator-min-microvolt = <2800000>;
                    regulator-max-microvolt = <3150000>;
                    regulator-always-on;
                    anatop-reg-offset = <0x120>;
                    anatop-vol-bit-shift = <8>;
                    anatop-vol-bit-width = <5>;
                    anatop-min-bit-val = <0>;
                    anatop-min-voltage = <2625000>;
                    anatop-max-voltage = <3400000>;
                    anatop-enable-bit = <0>;
                };

                reg_vdd2p5: regulator-2p5 {
                    compatible = "fsl,anatop-regulator";
                    regulator-name = "vdd2p5";
                    regulator-min-microvolt = <2250000>;
                    regulator-max-microvolt = <2750000>;
                    regulator-always-on;
                    anatop-reg-offset = <0x130>;
                    anatop-vol-bit-shift = <8>;
                    anatop-vol-bit-width = <5>;
                    anatop-min-bit-val = <0>;
                    anatop-min-voltage = <2100000>;
                    anatop-max-voltage = <2875000>;
                    anatop-enable-bit = <0>;
                    vin-supply = <&vgen5_reg>;
                };

                reg_arm: regulator-vddcore {
                    compatible = "fsl,anatop-regulator";
                    regulator-name = "vddarm";
                    regulator-min-microvolt = <725000>;
                    regulator-max-microvolt = <1450000>;
                    regulator-always-on;
                    anatop-reg-offset = <0x140>;
                    anatop-vol-bit-shift = <0>;
                    anatop-vol-bit-width = <5>;
                    anatop-delay-reg-offset = <0x170>;
                    anatop-delay-bit-shift = <24>;
                    anatop-delay-bit-width = <2>;
                    anatop-min-bit-val = <1>;
                    anatop-min-voltage = <725000>;
                    anatop-max-voltage = <1450000>;
                    vin-supply = <&sw1a_reg>;
                };

                reg_pu: regulator-vddpu {
                    compatible = "fsl,anatop-regulator";
                    regulator-name = "vddpu";
                    regulator-min-microvolt = <725000>;
                    regulator-max-microvolt = <1450000>;
                    regulator-enable-ramp-delay = <380>;
                    anatop-reg-offset = <0x140>;
                    anatop-vol-bit-shift = <9>;
                    anatop-vol-bit-width = <5>;
                    anatop-delay-reg-offset = <0x170>;
                    anatop-delay-bit-shift = <26>;
                    anatop-delay-bit-width = <2>;
                    anatop-min-bit-val = <1>;
                    anatop-min-voltage = <725000>;
                    anatop-max-voltage = <1450000>;
                    vin-supply = <&sw1c_reg>;
                };

                reg_soc: regulator-vddsoc {
                    compatible = "fsl,anatop-regulator";
                    regulator-name = "vddsoc";
                    regulator-min-microvolt = <725000>;
                    regulator-max-microvolt = <1450000>;
                    regulator-always-on;
                    anatop-reg-offset = <0x140>;
                    anatop-vol-bit-shift = <18>;
                    anatop-vol-bit-width = <5>;
                    anatop-delay-reg-offset = <0x170>;
                    anatop-delay-bit-shift = <28>;
                    anatop-delay-bit-width = <2>;
                    anatop-min-bit-val = <1>;
                    anatop-min-voltage = <725000>;
                    anatop-max-voltage = <1450000>;
                    vin-supply = <&sw1c_reg>;
                };

                tempmon: tempmon {
                    compatible = "fsl,imx6q-tempmon";
                    interrupt-parent = <&gpc>;
                    interrupts = <0 49 IRQ_TYPE_LEVEL_HIGH>;
                    fsl,tempmon = <&anatop>;
                    nvmem-cells = <&tempmon_calib>, <&tempmon_temp_grade>;
                    nvmem-cell-names = "calib", "temp_grade";
                    clocks = <&clks IMX6QDL_CLK_PLL3_USB_OTG>;
                    #thermal-sensor-cells = <0>;
                };
            };

            usbphy1: usbphy@20c9000 {
                compatible = "fsl,imx6q-usbphy", "fsl,imx23-usbphy";
                reg = <0x020c9000 0x1000>;
                interrupts = <0 44 IRQ_TYPE_LEVEL_HIGH>;
                clocks = <&clks IMX6QDL_CLK_USBPHY1>;
                fsl,anatop = <&anatop>;
            };

            usbphy2: usbphy@20ca000 {
                compatible = "fsl,imx6q-usbphy", "fsl,imx23-usbphy";
                reg = <0x020ca000 0x1000>;
                interrupts = <0 45 IRQ_TYPE_LEVEL_HIGH>;
                clocks = <&clks IMX6QDL_CLK_USBPHY2>;
                fsl,anatop = <&anatop>;
            };
            snvs: snvs@20cc000 {
                compatible = "fsl,sec-v4.0-mon", "syscon", "simple-mfd";
                reg = <0x020cc000 0x4000>;

                snvs_rtc: snvs-rtc-lp {
                    compatible = "fsl,sec-v4.0-mon-rtc-lp";
                    regmap = <&snvs>;
                    offset = <0x34>;
                    interrupts = <0 19 IRQ_TYPE_LEVEL_HIGH>,
                             <0 20 IRQ_TYPE_LEVEL_HIGH>;
                };

                snvs_poweroff: snvs-poweroff {
                    compatible = "syscon-poweroff";
                    regmap = <&snvs>;
                    offset = <0x38>;
                    value = <0x60>;
                    mask = <0x60>;
                    status = "okay";
                };

                snvs_pwrkey: snvs-powerkey {
                    compatible = "fsl,sec-v4.0-pwrkey";
                    regmap = <&snvs>;
                    interrupts = <GIC_SPI 4 IRQ_TYPE_LEVEL_HIGH>;
                    linux,keycode = <KEY_POWER>;
                    wakeup-source;
                    status = "okay";
                };

                snvs_lpgpr: snvs-lpgpr {
                    compatible = "fsl,imx6q-snvs-lpgpr";
                };
            };

            epit1: epit@20d0000 { /* EPIT1 */
                reg = <0x020d0000 0x4000>;
                interrupts = <0 56 IRQ_TYPE_LEVEL_HIGH>;
            };

            epit2: epit@20d4000 { /* EPIT2 */
                reg = <0x020d4000 0x4000>;
                interrupts = <0 57 IRQ_TYPE_LEVEL_HIGH>;
            };

            src: reset-controller@20d8000 {
                compatible = "fsl,imx6q-src", "fsl,imx51-src";
                reg = <0x020d8000 0x4000>;
                interrupts = <0 91 IRQ_TYPE_LEVEL_HIGH>,
                         <0 96 IRQ_TYPE_LEVEL_HIGH>;
                #reset-cells = <1>;
            };

            gpc: gpc@20dc000 {
                compatible = "fsl,imx6q-gpc";
                reg = <0x020dc000 0x4000>;
                interrupt-controller;
                #interrupt-cells = <3>;
                interrupts = <0 89 IRQ_TYPE_LEVEL_HIGH>;
                interrupt-parent = <&intc>;
                clocks = <&clks IMX6QDL_CLK_IPG>;
                clock-names = "ipg";

                pgc {
                    #address-cells = <1>;
                    #size-cells = <0>;

                    power-domain@0 {
                        reg = <0>;
                        #power-domain-cells = <0>;
                    };
                    pd_pu: power-domain@1 {
                        reg = <1>;
                        #power-domain-cells = <0>;
                        power-supply = <&reg_pu>;
                        clocks = <&clks IMX6QDL_CLK_GPU3D_CORE>,
                                 <&clks IMX6QDL_CLK_GPU3D_SHADER>,
                                 <&clks IMX6QDL_CLK_GPU2D_CORE>,
                                 <&clks IMX6QDL_CLK_GPU2D_AXI>,
                                 <&clks IMX6QDL_CLK_OPENVG_AXI>,
                                 <&clks IMX6QDL_CLK_VPU_AXI>;
                    };
                };
            };

            gpr: iomuxc-gpr@20e0000 {
                compatible = "fsl,imx6q-iomuxc-gpr", "syscon", "simple-mfd";
                reg = <0x20e0000 0x38>;

                mux: mux-controller {
                    compatible = "mmio-mux";
                    #mux-control-cells = <1>;
                                    mux-reg-masks = <0x04 0x00080000>, /* MIPI_IPU1_MUX */
                                    <0x04 0x00100000>, /* MIPI_IPU2_MUX */
                                    <0x0c 0x0000000c>, /* HDMI_MUX_CTL */
                                    <0x0c 0x000000c0>, /* LVDS0_MUX_CTL */
                                    <0x0c 0x00000300>, /* LVDS1_MUX_CTL */
                                    <0x28 0x00000003>, /* DCIC1_MUX_CTL */
                                    <0x28 0x0000000c>; /* DCIC2_MUX_CTL */
                };
            };

            iomuxc: pinctrl@20e0000 {
                compatible = "fsl,imx6dl-iomuxc", "fsl,imx6q-iomuxc";
                reg = <0x20e0000 0x4000>;
                pinctrl-names = "default";
                pinctrl-0 = <&pinctrl_hog>;

                    imx6qdl-sabresd {
                        pinctrl_hog: hoggrp {
                            fsl,pins = <
                                MX6QDL_PAD_NANDF_D0__GPIO2_IO00 0x1b0b0
                                MX6QDL_PAD_NANDF_D1__GPIO2_IO01 0x1b0b0
                                MX6QDL_PAD_NANDF_D2__GPIO2_IO02 0x1b0b0
                                MX6QDL_PAD_NANDF_D3__GPIO2_IO03 0x1b0b0
                                MX6QDL_PAD_GPIO_0__CCM_CLKO1    0x130b0
                                MX6QDL_PAD_NANDF_CLE__GPIO6_IO07 0x1b0b0
                                MX6QDL_PAD_ENET_TXD1__GPIO1_IO29 0x1b0b0
                                MX6QDL_PAD_EIM_D22__GPIO3_IO22  0x1b0b0
                                MX6QDL_PAD_ENET_CRS_DV__GPIO1_IO25 0x1b0b0
                            >;
                        };
                    
                        pinctrl_audmux: audmuxgrp {
                            fsl,pins = <
                                MX6QDL_PAD_CSI0_DAT7__AUD3_RXD      0x130b0
                                MX6QDL_PAD_CSI0_DAT4__AUD3_TXC      0x130b0
                                MX6QDL_PAD_CSI0_DAT5__AUD3_TXD      0x110b0
                                MX6QDL_PAD_CSI0_DAT6__AUD3_TXFS     0x130b0
                            >;
                        };
                       
                        pinctrl_ecspi1: ecspi1grp {
                            fsl,pins = <
                                MX6QDL_PAD_EIM_D17__ECSPI1_MISO     0x100b1
                                MX6QDL_PAD_EIM_D18__ECSPI1_MOSI     0x100b1
                                MX6QDL_PAD_EIM_D16__ECSPI1_SCLK     0x100b1
                                MX6QDL_PAD_ENET_TX_EN__GPIO1_IO28       0x1b0b0 /* spi gpio cs  */
                            >;
                        };
                      
 
                        pinctrl_ecspi2: ecspi2grp {
                            fsl,pins = <
                                MX6QDL_PAD_EIM_OE__ECSPI2_MISO     0x100b1
                                MX6QDL_PAD_EIM_CS1__ECSPI2_MOSI     0x100b1
                                MX6QDL_PAD_EIM_CS0__ECSPI2_SCLK     0x100b1
                                MX6QDL_PAD_CSI0_DAT11__ECSPI2_SS0   0x1b0b0 /* spi gpio cs  */
                            >;
                        };
                      
						// ADS1282 复位引脚配置
						pinctrl_ads1282_reset: ads1282resetgrp {
							fsl,pins = <
								MX6QDL_PAD_EIM_D20__GPIO3_IO20  0x1b0b0  // RESET引脚，默认高电平
							>;
						};
						// ADS1282 SYNC引脚配置
						pinctrl_ads1282_sync: ads1282syncgrp {
							fsl,pins = <
								MX6QDL_PAD_EIM_D21__GPIO3_IO21  0x1b0b0  // SYNC引脚，默认低电平
							>;
						};
						// ADS1282 PWDN引脚配置
						pinctrl_ads1282_pwdn: ads1282pwdngrp {
							fsl,pins = <
								MX6QDL_PAD_EIM_D19__GPIO3_IO19  0x1b0b0  // PWDN引脚，默认低电平
							>;
						};

						// ADS1282 中断引脚配置
						pinctrl_ads1282_irq: ads1282irqgrp {
							fsl,pins = <
								MX6QDL_PAD_EIM_A25__GPIO5_IO02   0x1b0a0  // DRDY引脚，上拉输入
							>;
						}; 
                        pinctrl_enet: enetgrp {
                            fsl,pins = <
                                MX6QDL_PAD_ENET_MDIO__ENET_MDIO     0x1b0b0
                                MX6QDL_PAD_ENET_MDC__ENET_MDC       0x1b0b0
                                MX6QDL_PAD_RGMII_TXC__RGMII_TXC     0x1b030
                                MX6QDL_PAD_RGMII_TD0__RGMII_TD0     0x1b030
                                MX6QDL_PAD_RGMII_TD1__RGMII_TD1     0x1b030
                                MX6QDL_PAD_RGMII_TD2__RGMII_TD2     0x1b030
                                MX6QDL_PAD_RGMII_TD3__RGMII_TD3     0x1b030
                                MX6QDL_PAD_RGMII_TX_CTL__RGMII_TX_CTL   0x1b030
                                MX6QDL_PAD_ENET_REF_CLK__ENET_TX_CLK    0x1b0b0
                                MX6QDL_PAD_RGMII_RXC__RGMII_RXC     0x1b030
                                MX6QDL_PAD_RGMII_RD0__RGMII_RD0     0x1b030
                                MX6QDL_PAD_RGMII_RD1__RGMII_RD1     0x1b030
                                MX6QDL_PAD_RGMII_RD2__RGMII_RD2     0x1b030
                                MX6QDL_PAD_RGMII_RD3__RGMII_RD3     0x1b030
                                MX6QDL_PAD_RGMII_RX_CTL__RGMII_RX_CTL   0x1b030
                                MX6QDL_PAD_GPIO_16__ENET_REF_CLK    0x4001b0a8
                            >;
                        };

                        pinctrl_gpio_keys: gpio_keysgrp {
                            fsl,pins = <
                                MX6QDL_PAD_EIM_D29__GPIO3_IO29 0x1b0b0
                                MX6QDL_PAD_GPIO_4__GPIO1_IO04  0x1b0b0
                                MX6QDL_PAD_GPIO_5__GPIO1_IO05  0x1b0b0
                            >;
                        };

                        pinctrl_hdmi_cec: hdmicecgrp {
                            fsl,pins = <
                                MX6QDL_PAD_KEY_ROW2__HDMI_TX_CEC_LINE   0x1f8b0
                            >;
                        };
                        
                        pinctrl_hp: hpgrp {
                            fsl,pins = <
                                MX6QDL_PAD_SD3_RST__GPIO7_IO08          0x1b0b0
                                MX6QDL_PAD_GPIO_9__GPIO1_IO09           0x1b0b0
                            >;
                        };
                        
                        pinctrl_i2c1: i2c1grp {
                            fsl,pins = <
                                MX6QDL_PAD_CSI0_DAT8__I2C1_SDA      0x4001b8b1
                                MX6QDL_PAD_CSI0_DAT9__I2C1_SCL      0x4001b8b1
                            >;
                        };
                        
                        pinctrl_i2c1_mma8451_int: i2c1mma8451intgrp {
                            fsl,pins = <
                                MX6QDL_PAD_SD1_CMD__GPIO1_IO18      0xb0b1
                            >;
                        };
                        
                        pinctrl_i2c2: i2c2grp {
                            fsl,pins = <
                                MX6QDL_PAD_KEY_COL3__I2C2_SCL       0x4001b8b1
                                MX6QDL_PAD_KEY_ROW3__I2C2_SDA       0x4001b8b1
                            >;
                        };
                        
                        pinctrl_i2c2_egalax_int: i2c2egalaxintgrp {
                            fsl,pins = <
                                MX6QDL_PAD_NANDF_ALE__GPIO6_IO08    0x1b0b0
                            >;
                        };
                        
                        pinctrl_i2c3: i2c3grp {
                            fsl,pins = <
                                MX6QDL_PAD_GPIO_3__I2C3_SCL     0x4001b8b1
                                MX6QDL_PAD_GPIO_6__I2C3_SDA     0x4001b8b1
                            >;
                        };
                        
                        pinctrl_i2c3_isl29023_int: i2c3isl29023intgrp {
                            fsl,pins = <
                                MX6QDL_PAD_EIM_DA9__GPIO3_IO09      0xb0b1
                            >;
                        };
                        
                        pinctrl_i2c3_mag3110_int: i2c3mag3110intgrp {
                            fsl,pins = <
                                MX6QDL_PAD_EIM_D16__GPIO3_IO16      0xb0b1
                            >;
                        };
                        
                        pinctrl_ipu1_csi0: ipu1csi0grp {
                            fsl,pins = <
                                MX6QDL_PAD_CSI0_DAT12__IPU1_CSI0_DATA12    0x1b0b0
                                MX6QDL_PAD_CSI0_DAT13__IPU1_CSI0_DATA13    0x1b0b0
                                MX6QDL_PAD_CSI0_DAT14__IPU1_CSI0_DATA14    0x1b0b0
                                MX6QDL_PAD_CSI0_DAT15__IPU1_CSI0_DATA15    0x1b0b0
                                MX6QDL_PAD_CSI0_DAT16__IPU1_CSI0_DATA16    0x1b0b0
                                MX6QDL_PAD_CSI0_DAT17__IPU1_CSI0_DATA17    0x1b0b0
                                MX6QDL_PAD_CSI0_DAT18__IPU1_CSI0_DATA18    0x1b0b0
                                MX6QDL_PAD_CSI0_DAT19__IPU1_CSI0_DATA19    0x1b0b0
                                MX6QDL_PAD_CSI0_PIXCLK__IPU1_CSI0_PIXCLK   0x1b0b0
                                MX6QDL_PAD_CSI0_MCLK__IPU1_CSI0_HSYNC      0x1b0b0
                                MX6QDL_PAD_CSI0_VSYNC__IPU1_CSI0_VSYNC     0x1b0b0
                            >;
                        };
                        
                        pinctrl_ov5640: ov5640grp {
                            fsl,pins = <
                                MX6QDL_PAD_SD1_DAT2__GPIO1_IO19 0x1b0b0
                                MX6QDL_PAD_SD1_CLK__GPIO1_IO20  0x1b0b0
                            >;
                        };
                        
                        pinctrl_ov5642: ov5642grp {
                            fsl,pins = <
                                MX6QDL_PAD_SD1_DAT0__GPIO1_IO16 0x1b0b0
                                MX6QDL_PAD_SD1_DAT1__GPIO1_IO17 0x1b0b0
                            >;
                        };
                        
                        pinctrl_pcie: pciegrp {
                            fsl,pins = <
                                MX6QDL_PAD_GPIO_17__GPIO7_IO12  0x1b0b0
                            >;
                        };
/* 
                        pinctrl_pcie_reg: pciereggrp {
                            fsl,pins = <
                                MX6QDL_PAD_EIM_D19__GPIO3_IO19  0x1b0b0
                            >;
                        };
*/
                        pinctrl_pwm1: pwm1grp {
                            fsl,pins = <
                                MX6QDL_PAD_SD1_DAT3__PWM1_OUT       0x1b0b1
                            >;
                        };
                        
                        pinctrl_sensors_reg: sensorsreggrp {
                            fsl,pins = <
                                MX6QDL_PAD_EIM_EB3__GPIO2_IO31      0x1b0b0
                            >;
                        };
                        
                        pinctrl_uart1: uart1grp {
                            fsl,pins = <
                                MX6QDL_PAD_SD3_DAT7__UART1_TX_DATA  0x1b0b1
                                MX6QDL_PAD_SD3_DAT6__UART1_RX_DATA  0x1b0b1
                            >;
                        };
                        
                        pinctrl_usbotg: usbotggrp {
                            fsl,pins = <
                                MX6QDL_PAD_ENET_RX_ER__USB_OTG_ID   0x17059
                            >;
                        };
                        
                        pinctrl_usdhc2: usdhc2grp {
                            fsl,pins = <
                                MX6QDL_PAD_SD2_CMD__SD2_CMD     0x17059
                                MX6QDL_PAD_SD2_CLK__SD2_CLK     0x10059
                                MX6QDL_PAD_SD2_DAT0__SD2_DATA0      0x17059
                                MX6QDL_PAD_SD2_DAT1__SD2_DATA1      0x17059
                                MX6QDL_PAD_SD2_DAT2__SD2_DATA2      0x17059
                                MX6QDL_PAD_SD2_DAT3__SD2_DATA3      0x17059
                            >;
                        };
                        
                        pinctrl_usdhc3: usdhc3grp {
                            fsl,pins = <
                                MX6QDL_PAD_SD3_CMD__SD3_CMD     0x17059
                                MX6QDL_PAD_SD3_CLK__SD3_CLK     0x10059
                                MX6QDL_PAD_SD3_DAT0__SD3_DATA0      0x17059
                                MX6QDL_PAD_SD3_DAT1__SD3_DATA1      0x17059
                                MX6QDL_PAD_SD3_DAT2__SD3_DATA2      0x17059
                                MX6QDL_PAD_SD3_DAT3__SD3_DATA3      0x17059
                                MX6QDL_PAD_SD3_DAT4__SD3_DATA4      0x17059
                                MX6QDL_PAD_SD3_DAT5__SD3_DATA5      0x17059
                                MX6QDL_PAD_SD3_DAT6__SD3_DATA6      0x17059
                                MX6QDL_PAD_SD3_DAT7__SD3_DATA7      0x17059
                            >;
                        };
                        
                        pinctrl_usdhc4: usdhc4grp {
                            fsl,pins = <
                                MX6QDL_PAD_SD4_CMD__SD4_CMD     0x17059
                                MX6QDL_PAD_SD4_CLK__SD4_CLK     0x10059
                                MX6QDL_PAD_SD4_DAT0__SD4_DATA0      0x17059
                                MX6QDL_PAD_SD4_DAT1__SD4_DATA1      0x17059
                                MX6QDL_PAD_SD4_DAT2__SD4_DATA2      0x17059
                                MX6QDL_PAD_SD4_DAT3__SD4_DATA3      0x17059
                                MX6QDL_PAD_SD4_DAT4__SD4_DATA4      0x17059
                                MX6QDL_PAD_SD4_DAT5__SD4_DATA5      0x17059
                                MX6QDL_PAD_SD4_DAT6__SD4_DATA6      0x17059
                                MX6QDL_PAD_SD4_DAT7__SD4_DATA7      0x17059
                            >;
                        };
                        
                        pinctrl_wdog: wdoggrp {
                            fsl,pins = <
                                MX6QDL_PAD_GPIO_1__WDOG2_B      0x1b0b0
                            >;
                        };
                    };
            };

            dcic2: dcic@20e8000 {
                reg = <0x020e8000 0x4000>;
                interrupts = <0 125 IRQ_TYPE_LEVEL_HIGH>;
            };

            sdma: dma-controller@20ec000 {
                compatible = "fsl,imx6q-sdma", "fsl,imx35-sdma";
                reg = <0x020ec000 0x4000>;
                interrupts = <0 2 IRQ_TYPE_LEVEL_HIGH>;
                clocks = <&clks IMX6QDL_CLK_SDMA>,
                     <&clks IMX6QDL_CLK_SDMA>;
                clock-names = "ipg", "ahb";
                #dma-cells = <3>;
                fsl,sdma-ram-script-name = "imx/sdma/sdma-imx6q.bin";
            };
        };

        aips2: bus@2100000 { /* AIPS2 */
            compatible = "fsl,aips-bus", "simple-bus";
            #address-cells = <1>;
            #size-cells = <1>;
            reg = <0x02100000 0x100000>;
            ranges;

            crypto: crypto@2100000 {
                compatible = "fsl,sec-v4.0";
                #address-cells = <1>;
                #size-cells = <1>;
                reg = <0x2100000 0x10000>;
                ranges = <0 0x2100000 0x10000>;
                clocks = <&clks IMX6QDL_CLK_CAAM_MEM>,
                     <&clks IMX6QDL_CLK_CAAM_ACLK>,
                     <&clks IMX6QDL_CLK_CAAM_IPG>,
                     <&clks IMX6QDL_CLK_EIM_SLOW>;
                clock-names = "mem", "aclk", "ipg", "emi_slow";

                sec_jr0: jr@1000 {
                    compatible = "fsl,sec-v4.0-job-ring";
                    reg = <0x1000 0x1000>;
                    interrupts = <GIC_SPI 105 IRQ_TYPE_LEVEL_HIGH>;
                };

                sec_jr1: jr@2000 {
                    compatible = "fsl,sec-v4.0-job-ring";
                    reg = <0x2000 0x1000>;
                    interrupts = <GIC_SPI 106 IRQ_TYPE_LEVEL_HIGH>;
                };
            };

            aipstz@217c000 { /* AIPSTZ2 */
                reg = <0x0217c000 0x4000>;
            };

            usbotg: usb@2184000 {
                compatible = "fsl,imx6q-usb", "fsl,imx27-usb";
                reg = <0x02184000 0x200>;
                interrupts = <0 43 IRQ_TYPE_LEVEL_HIGH>;
                clocks = <&clks IMX6QDL_CLK_USBOH3>;
                fsl,usbphy = <&usbphy1>;
                fsl,usbmisc = <&usbmisc 0>;
                ahb-burst-config = <0x0>;
                tx-burst-size-dword = <0x10>;
                rx-burst-size-dword = <0x10>;
                status = "okay";
                vbus-supply = <&reg_usb_otg_vbus>;
                pinctrl-names = "default";
                pinctrl-0 = <&pinctrl_usbotg>;
                disable-over-current;
            };

            usbh1: usb@2184200 {
                compatible = "fsl,imx6q-usb", "fsl,imx27-usb";
                reg = <0x02184200 0x200>;
                interrupts = <0 40 IRQ_TYPE_LEVEL_HIGH>;
                clocks = <&clks IMX6QDL_CLK_USBOH3>;
                fsl,usbphy = <&usbphy2>;
                fsl,usbmisc = <&usbmisc 1>;
                dr_mode = "host";
                ahb-burst-config = <0x0>;
                tx-burst-size-dword = <0x10>;
                rx-burst-size-dword = <0x10>;
                status = "okay";
                vbus-supply = <&reg_usb_h1_vbus>;
            };

            usbh2: usb@2184400 {
                compatible = "fsl,imx6q-usb", "fsl,imx27-usb";
                reg = <0x02184400 0x200>;
                interrupts = <0 41 IRQ_TYPE_LEVEL_HIGH>;
                clocks = <&clks IMX6QDL_CLK_USBOH3>;
                fsl,usbphy = <&usbphynop1>;
                phy_type = "hsic";
                fsl,usbmisc = <&usbmisc 2>;
                dr_mode = "host";
                ahb-burst-config = <0x0>;
                tx-burst-size-dword = <0x10>;
                rx-burst-size-dword = <0x10>;
                status = "disabled";
            };

            usbh3: usb@2184600 {
                compatible = "fsl,imx6q-usb", "fsl,imx27-usb";
                reg = <0x02184600 0x200>;
                interrupts = <0 42 IRQ_TYPE_LEVEL_HIGH>;
                clocks = <&clks IMX6QDL_CLK_USBOH3>;
                fsl,usbphy = <&usbphynop2>;
                phy_type = "hsic";
                fsl,usbmisc = <&usbmisc 3>;
                dr_mode = "host";
                ahb-burst-config = <0x0>;
                tx-burst-size-dword = <0x10>;
                rx-burst-size-dword = <0x10>;
                status = "disabled";
            };

            usbmisc: usbmisc@2184800 {
                #index-cells = <1>;
                compatible = "fsl,imx6q-usbmisc";
                reg = <0x02184800 0x200>;
                clocks = <&clks IMX6QDL_CLK_USBOH3>;
            };

            fec: ethernet@2188000 {
                compatible = "fsl,imx6q-fec";
                reg = <0x02188000 0x4000>;
                interrupt-names = "int0", "pps";
                interrupts = <0 118 IRQ_TYPE_LEVEL_HIGH>,
                         <0 119 IRQ_TYPE_LEVEL_HIGH>;
                clocks = <&clks IMX6QDL_CLK_ENET>,
                     <&clks IMX6QDL_CLK_ENET>,
                     <&clks IMX6QDL_CLK_ENET_REF>,
                     <&clks IMX6QDL_CLK_ENET_REF_SEL>;
                clock-names = "ipg", "ahb", "ptp", "enet_clk_ref";
                fsl,stop-mode = <&gpr 0x34 27>;
                nvmem-cells = <&fec_mac_addr>;
                nvmem-cell-names = "mac-address";
                status = "okay";
                pinctrl-names = "default";
                pinctrl-0 = <&pinctrl_enet>;
                phy-mode = "rgmii-id";
                phy-handle = <&phy>;
                fsl,magic-packet;

                mdio {
                    #address-cells = <0x01>;
                    #size-cells = <0x00>;

                    phy:ethernet-phy@0 {
                        reg = <0x00>;
                        qca,clk-out-frequency = <125000000>;
                        reset-gpios = <&gpio1 25 GPIO_ACTIVE_LOW>;
                        reset-assert-us = <10000>;
                    };
                };
            };

            mlb@218c000 {
                reg = <0x0218c000 0x4000>;
                interrupts = <0 53 IRQ_TYPE_LEVEL_HIGH>,
                         <0 117 IRQ_TYPE_LEVEL_HIGH>,
                         <0 126 IRQ_TYPE_LEVEL_HIGH>;
            };

            usdhc1: mmc@2190000 {
                compatible = "fsl,imx6q-usdhc";
                reg = <0x02190000 0x4000>;
                interrupts = <0 22 IRQ_TYPE_LEVEL_HIGH>;
                clocks = <&clks IMX6QDL_CLK_USDHC1>,
                     <&clks IMX6QDL_CLK_USDHC1>,
                     <&clks IMX6QDL_CLK_USDHC1>;
                clock-names = "ipg", "ahb", "per";
                bus-width = <4>;
                status = "disabled";
            };

            usdhc2: mmc@2194000 {
                compatible = "fsl,imx6q-usdhc";
                reg = <0x02194000 0x4000>;
                interrupts = <0 23 IRQ_TYPE_LEVEL_HIGH>;
                clocks = <&clks IMX6QDL_CLK_USDHC2>,
                     <&clks IMX6QDL_CLK_USDHC2>,
                     <&clks IMX6QDL_CLK_USDHC2>;
                clock-names = "ipg", "ahb", "per";
                bus-width = <0x08>;
                status = "okay";
                pinctrl-names = "default";
                pinctrl-0 = <&pinctrl_usdhc2>;
                    cd-gpios = <&gpio1 4 GPIO_ACTIVE_LOW>;
                            /*wp-gpios = <&gpio2 3 GPIO_ACTIVE_HIGH>;*/
            };

            usdhc3: mmc@2198000 {
                compatible = "fsl,imx6q-usdhc";
                reg = <0x02198000 0x4000>;
                interrupts = <0 24 IRQ_TYPE_LEVEL_HIGH>;
                clocks = <&clks IMX6QDL_CLK_USDHC3>,
                     <&clks IMX6QDL_CLK_USDHC3>,
                     <&clks IMX6QDL_CLK_USDHC3>;
                clock-names = "ipg", "ahb", "per";
                bus-width = <0x08>;
                status = "disabled";
                pinctrl-names = "default";
                pinctrl-0 = <&pinctrl_usdhc3>;
                            cd-gpios = <&gpio2 0 GPIO_ACTIVE_LOW>;
                            wp-gpios = <&gpio2 1 GPIO_ACTIVE_HIGH>;
            };

            usdhc4: mmc@219c000 {
                compatible = "fsl,imx6q-usdhc";
                reg = <0x0219c000 0x4000>;
                interrupts = <0 25 IRQ_TYPE_LEVEL_HIGH>;
                clocks = <&clks IMX6QDL_CLK_USDHC4>,
                     <&clks IMX6QDL_CLK_USDHC4>,
                     <&clks IMX6QDL_CLK_USDHC4>;
                clock-names = "ipg", "ahb", "per";
                bus-width = <0x08>;
                status = "okay";
                pinctrl-names = "default";
                pinctrl-0 = <&pinctrl_usdhc4>;
                non-removable;
                no-1-8-v;
            };

            i2c1: i2c@21a0000 {
                #address-cells = <1>;
                #size-cells = <0>;
                compatible = "fsl,imx6q-i2c", "fsl,imx21-i2c";
                reg = <0x021a0000 0x4000>;
                interrupts = <0 36 IRQ_TYPE_LEVEL_HIGH>;
                clocks = <&clks IMX6QDL_CLK_I2C1>;
                status = "okay";
                clock-frequency = <100000>;
                pinctrl-names = "default";
                pinctrl-0 = <&pinctrl_i2c1>;
            };

            i2c2: i2c@21a4000 {
                #address-cells = <1>;
                #size-cells = <0>;
                compatible = "fsl,imx6q-i2c", "fsl,imx21-i2c";
                reg = <0x021a4000 0x4000>;
                interrupts = <0 37 IRQ_TYPE_LEVEL_HIGH>;
                clocks = <&clks IMX6QDL_CLK_I2C2>;
                status = "okay";
                clock-frequency = <100000>;
                pinctrl-names = "default";
                pinctrl-0 = <&pinctrl_i2c2>;
                pmic: pmic@8 {
                    compatible = "fsl,pfuze100";
                    reg = <0x08>;
                    regulators {
                        sw1a_reg: sw1ab {
                            regulator-min-microvolt = <300000>;
                            regulator-max-microvolt = <1875000>;
                            regulator-boot-on;
                            regulator-always-on;
                            regulator-ramp-delay = <6250>;
                        };
                    
                        sw1c_reg: sw1c {
                            regulator-min-microvolt = <300000>;
                            regulator-max-microvolt = <1875000>;
                            regulator-boot-on;
                            regulator-always-on;
                            regulator-ramp-delay = <6250>;
                        };
                    
                        sw2_reg: sw2 {
                            regulator-min-microvolt = <800000>;
                            regulator-max-microvolt = <3300000>;
                            regulator-boot-on;
                            regulator-always-on;
                            regulator-ramp-delay = <6250>;
                        };
                    
                        sw3a_reg: sw3a {
                            regulator-min-microvolt = <400000>;
                            regulator-max-microvolt = <1975000>;
                            regulator-boot-on;
                            regulator-always-on;
                        };
                    
                        sw3b_reg: sw3b {
                            regulator-min-microvolt = <400000>;
                            regulator-max-microvolt = <1975000>;
                            regulator-boot-on;
                            regulator-always-on;
                        };
                    
                        sw4_reg: sw4 {
                            regulator-min-microvolt = <800000>;
                            regulator-max-microvolt = <3300000>;
                            regulator-always-on;
                        };
                    
                        swbst_reg: swbst {
                            regulator-min-microvolt = <5000000>;
                            regulator-max-microvolt = <5150000>;
                        };
                    
                        snvs_reg: vsnvs {
                            regulator-min-microvolt = <1000000>;
                            regulator-max-microvolt = <3000000>;
                            regulator-boot-on;
                            regulator-always-on;
                        };
                    
                        vref_reg: vrefddr {
                            regulator-boot-on;
                            regulator-always-on;
                        };
                    
                        vgen1_reg: vgen1 {
                            regulator-min-microvolt = <800000>;
                            regulator-max-microvolt = <1550000>;
                        };
                    
                        vgen2_reg: vgen2 {
                            regulator-min-microvolt = <800000>;
                            regulator-max-microvolt = <1550000>;
                        };
                    
                        vgen3_reg: vgen3 {
                            regulator-min-microvolt = <1800000>;
                            regulator-max-microvolt = <3300000>;
                        };
                    
                        vgen4_reg: vgen4 {
                            regulator-min-microvolt = <1800000>;
                            regulator-max-microvolt = <3300000>;
                            regulator-always-on;
                        };
                    
                        vgen5_reg: vgen5 {
                            regulator-min-microvolt = <1800000>;
                            regulator-max-microvolt = <3300000>;
                            regulator-always-on;
                        };
                    
                        vgen6_reg: vgen6 {
                            regulator-min-microvolt = <1800000>;
                            regulator-max-microvolt = <3300000>;
                            regulator-always-on;
                        };
                    };
                };
            };

            i2c3: i2c@21a8000 {
                #address-cells = <1>;
                #size-cells = <0>;
                compatible = "fsl,imx6q-i2c", "fsl,imx21-i2c";
                reg = <0x021a8000 0x4000>;
                interrupts = <0 38 IRQ_TYPE_LEVEL_HIGH>;
                clocks = <&clks IMX6QDL_CLK_I2C3>;
                status = "okay";
                clock-frequency = <100000>;
                pinctrl-names = "default";
                pinctrl-0 = <&pinctrl_i2c3>;
            };

            romcp@21ac000 {
                reg = <0x021ac000 0x4000>;
            };

            mmdc0: memory-controller@21b0000 { /* MMDC0 */
                compatible = "fsl,imx6q-mmdc";
                reg = <0x021b0000 0x4000>;
                clocks = <&clks IMX6QDL_CLK_MMDC_P0_IPG>;
            };

            mmdc1: memory-controller@21b4000 { /* MMDC1 */
                compatible = "fsl,imx6q-mmdc";
                reg = <0x021b4000 0x4000>;
                status = "disabled";
            };

            weim: weim@21b8000 {
                #address-cells = <2>;
                #size-cells = <1>;
                compatible = "fsl,imx6q-weim";
                reg = <0x021b8000 0x4000>;
                interrupts = <0 14 IRQ_TYPE_LEVEL_HIGH>;
                clocks = <&clks IMX6QDL_CLK_EIM_SLOW>;
                fsl,weim-cs-gpr = <&gpr>;
                status = "disabled";
            };

            ocotp: efuse@21bc000 {
                compatible = "fsl,imx6q-ocotp","syscon";
                reg = <0x21bc000 0x4000>;
                clocks = <&clks IMX6QDL_CLK_IIM>;
                #address-cells = <0x01>;
                #size-cells = <0x01>;
                cpu_speed_grade: speed-grade@10 {
                    reg = <0x10 4>;
                };

                tempmon_calib: calib@38 {
                    reg = <0x38 4>;
                };

                tempmon_temp_grade: temp-grade@20 {
                    reg = <0x20 4>;
                };

                fec_mac_addr: mac-addr@88 {
                    reg = <0x88 6>;
                };
            };

            tzasc@21d0000 { /* TZASC1 */
                reg = <0x021d0000 0x4000>;
                interrupts = <0 108 IRQ_TYPE_LEVEL_HIGH>;
            };

            tzasc@21d4000 { /* TZASC2 */
                reg = <0x021d4000 0x4000>;
                interrupts = <0 109 IRQ_TYPE_LEVEL_HIGH>;
            };

            audmux@21d8000 {
                compatible = "fsl,imx6q-audmux","fsl,imx31-audmux";
                reg = <0x21d8000 0x4000>;
                status = "disabled";
                pinctrl-names = "default";
                pinctrl-0 = <0x53>;
            };

            mipi_csi: mipi@21dc000 {
                compatible = "fsl,imx6-mipi-csi2";
                reg = <0x021dc000 0x4000>;
                #address-cells = <1>;
                #size-cells = <0>;
                interrupts = <0 100 0x04>, <0 101 0x04>;
                clocks = <&clks IMX6QDL_CLK_HSI_TX>,
                     <&clks IMX6QDL_CLK_VIDEO_27M>,
                     <&clks IMX6QDL_CLK_EIM_PODF>;
                clock-names = "dphy", "ref", "pix";
                status = "disabled";
            };

            mipi@21e0000 {
                reg = <0x21e0000 0x4000>;
                status = "disabled";
            };

            vdoa@21e4000 {
                compatible = "fsl,imx6q-vdoa";
                reg = <0x021e4000 0x4000>;
                interrupts = <0 18 IRQ_TYPE_LEVEL_HIGH>;
                clocks = <&clks IMX6QDL_CLK_VDOA>;
            };

            uart2: serial@21e8000 {
                compatible = "fsl,imx6q-uart", "fsl,imx21-uart";
                reg = <0x021e8000 0x4000>;
                interrupts = <0 27 IRQ_TYPE_LEVEL_HIGH>;
                clocks = <&clks IMX6QDL_CLK_UART_IPG>,
                     <&clks IMX6QDL_CLK_UART_SERIAL>;
                clock-names = "ipg", "per";
                dmas = <&sdma 27 4 0>, <&sdma 28 4 0>;
                dma-names = "rx", "tx";
                status = "disabled";
            };

            uart3: serial@21ec000 {
                compatible = "fsl,imx6q-uart", "fsl,imx21-uart";
                reg = <0x021ec000 0x4000>;
                interrupts = <0 28 IRQ_TYPE_LEVEL_HIGH>;
                clocks = <&clks IMX6QDL_CLK_UART_IPG>,
                     <&clks IMX6QDL_CLK_UART_SERIAL>;
                clock-names = "ipg", "per";
                dmas = <&sdma 29 4 0>, <&sdma 30 4 0>;
                dma-names = "rx", "tx";
                status = "disabled";
            };

            uart4: serial@21f0000 {
                compatible = "fsl,imx6q-uart", "fsl,imx21-uart";
                reg = <0x021f0000 0x4000>;
                interrupts = <0 29 IRQ_TYPE_LEVEL_HIGH>;
                clocks = <&clks IMX6QDL_CLK_UART_IPG>,
                     <&clks IMX6QDL_CLK_UART_SERIAL>;
                clock-names = "ipg", "per";
                dmas = <&sdma 31 4 0>, <&sdma 32 4 0>;
                dma-names = "rx", "tx";
                status = "disabled";
            };

            uart5: serial@21f4000 {
                compatible = "fsl,imx6q-uart", "fsl,imx21-uart";
                reg = <0x021f4000 0x4000>;
                interrupts = <0 30 IRQ_TYPE_LEVEL_HIGH>;
                clocks = <&clks IMX6QDL_CLK_UART_IPG>,
                     <&clks IMX6QDL_CLK_UART_SERIAL>;
                clock-names = "ipg", "per";
                dmas = <&sdma 33 4 0>, <&sdma 34 4 0>;
                dma-names = "rx", "tx";
                status = "disabled";
            };
            
            pre1: pre@21c8000 {
                compatible = "fsl,imx6qp-pre";
                reg = <0x021c8000 0x1000>;
                interrupts = <GIC_SPI 90 IRQ_TYPE_EDGE_RISING>;
                clocks = <&clks IMX6QDL_CLK_PRE0>;
                clock-names = "axi";
                fsl,iram = <&ocram2>;
            };

            pre2: pre@21c9000 {
                compatible = "fsl,imx6qp-pre";
                reg = <0x021c9000 0x1000>;
                interrupts = <GIC_SPI 97 IRQ_TYPE_EDGE_RISING>;
                clocks = <&clks IMX6QDL_CLK_PRE1>;
                clock-names = "axi";
                fsl,iram = <&ocram2>;
            };

            pre3: pre@21ca000 {
                compatible = "fsl,imx6qp-pre";
                reg = <0x021ca000 0x1000>;
                interrupts = <GIC_SPI 98 IRQ_TYPE_EDGE_RISING>;
                clocks = <&clks IMX6QDL_CLK_PRE2>;
                clock-names = "axi";
                fsl,iram = <&ocram3>;
            };

            pre4: pre@21cb000 {
                compatible = "fsl,imx6qp-pre";
                reg = <0x021cb000 0x1000>;
                interrupts = <GIC_SPI 99 IRQ_TYPE_EDGE_RISING>;
                clocks = <&clks IMX6QDL_CLK_PRE3>;
                clock-names = "axi";
                fsl,iram = <&ocram3>;
            };

            prg1: prg@21cc000 {
                compatible = "fsl,imx6qp-prg";
                reg = <0x021cc000 0x1000>;
                clocks = <&clks IMX6QDL_CLK_PRG0_APB>,
                     <&clks IMX6QDL_CLK_PRG0_AXI>;
                clock-names = "ipg", "axi";
                fsl,pres = <&pre1>, <&pre2>, <&pre3>;
            };

            prg2: prg@21cd000 {
                compatible = "fsl,imx6qp-prg";
                reg = <0x021cd000 0x1000>;
                clocks = <&clks IMX6QDL_CLK_PRG1_APB>,
                     <&clks IMX6QDL_CLK_PRG1_AXI>;
                clock-names = "ipg", "axi";
                fsl,pres = <&pre4>, <&pre2>, <&pre3>;
            };
        };

       ipu1: ipu@2400000 {
            #address-cells = <0x01>;
            #size-cells = <0x00>;
            compatible = "fsl,imx6qp-ipu","fsl,imx6q-ipu";
            reg = <0x2400000 0x400000>;
            interrupts = <0 6 IRQ_TYPE_LEVEL_HIGH>,
                        <0 5 IRQ_TYPE_LEVEL_HIGH>;
            clocks = <&clks IMX6QDL_CLK_IPU1>,
                    <&clks IMX6QDL_CLK_IPU1_DI0>,
                    <&clks IMX6QDL_CLK_IPU1_DI1>;
            clock-names = "bus", "di0", "di1";  
            resets = <&src 2>;
            fsl,prg = <0x63>;
        };

        ocram: sram@900000 {
            compatible = "mmio-sram";
            reg = <0x00900000 0x40000>;
            ranges = <0 0x00900000 0x40000>;
            #address-cells = <1>;
            #size-cells = <1>;
            clocks = <&clks IMX6QDL_CLK_OCRAM>;
        };

        sata: sata@2200000 {
            compatible = "fsl,imx6q-ahci";
            reg = <0x2200000 0x4000>;
            interrupts = <0 39 IRQ_TYPE_LEVEL_HIGH>;
            clocks = <&clks IMX6QDL_CLK_SATA>,
                 <&clks IMX6QDL_CLK_SATA_REF_100M>,
                 <&clks IMX6QDL_CLK_AHB>;
            clock-names = "sata", "sata_ref", "ahb";
            status = "okay";
        };

        gpu_vg: gpu@2204000 {
            compatible = "vivante,gc";
            reg = <0x2204000 0x4000>;
            interrupts = <0 11 IRQ_TYPE_LEVEL_HIGH>;
            clocks = <&clks IMX6QDL_CLK_OPENVG_AXI>,
                 <&clks IMX6QDL_CLK_GPU2D_CORE>;
            clock-names = "bus", "core";
            power-domains = <&pd_pu>;
            #cooling-cells = <0x02>;
        };

        ipu2: ipu@2800000 {
            #address-cells = <0x01>;
            #size-cells = <0x00>;
            compatible = "fsl,imx6qp-ipu","fsl,imx6q-ipu";
            reg = <0x2800000 0x400000>;
            interrupts = <0 8 IRQ_TYPE_LEVEL_HIGH>,
                     <0 7 IRQ_TYPE_LEVEL_HIGH>;
            clocks = <&clks IMX6QDL_CLK_IPU2>,
                 <&clks IMX6QDL_CLK_IPU2_DI0>,
                 <&clks IMX6QDL_CLK_IPU2_DI1>;
            clock-names = "bus", "di0", "di1";
            resets = <&src 4>;
            fsl,prg = <0x6f>;
        };

        ocram2: sram@940000 {
            compatible = "mmio-sram";
            reg = <0x00940000 0x20000>;
            ranges = <0 0x00940000 0x20000>;
            #address-cells = <1>;
            #size-cells = <1>;
            clocks = <&clks IMX6QDL_CLK_OCRAM>;
        };
        ocram3: sram@960000 {
            compatible = "mmio-sram";
            reg = <0x00960000 0x20000>;
            ranges = <0 0x00960000 0x20000>;
            #address-cells = <1>;
            #size-cells = <1>;
            clocks = <&clks IMX6QDL_CLK_OCRAM>;
        };
    };
    reserved-memory {
        #address-cells = <1>;
        #size-cells = <1>;
        ranges;
        cpu3: imx6q_amp@8EC00000 {
            reg = <0x8EC00000 0x01400000>;
            no-map;
        };
    };

    imx6q_amp{
        compatible = "nxp,imx6q-amp";
        interrupt-parent = <&intc>;
        nxp,sgi-intid = <15>;
    };
};
#include "reboot.dtsi"
